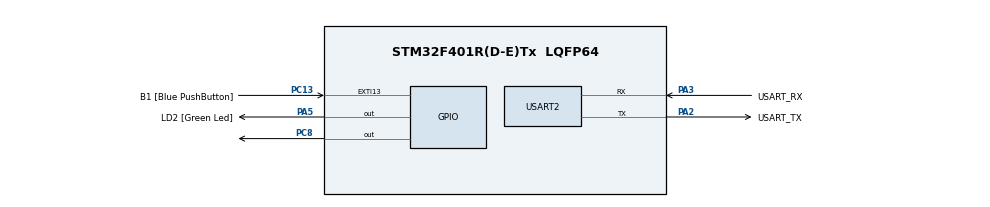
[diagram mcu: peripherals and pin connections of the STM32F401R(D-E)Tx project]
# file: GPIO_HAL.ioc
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Mcu.Family=STM32F4
Mcu.Name=STM32F401R(D-E)Tx
Mcu.Package=LQFP64
NVIC.PriorityGroup=NVIC_PRIORITYGROUP_4
NVIC.USART2_IRQn=true\:3\:0\:true\:false\:true\:true\:true\:true
PA13.GPIO_Label=TMS
PA13.Mode=Serial_Wire
PA13.Signal=SYS_JTMS-SWDIO
PA14.GPIO_Label=TCK
PA14.Mode=Serial_Wire
PA14.Signal=SYS_JTCK-SWCLK
PA2.GPIO_Label=USART_TX
PA2.GPIO_Mode=GPIO_MODE_AF_PP
PA2.GPIO_PuPd=GPIO_NOPULL
PA2.GPIO_Speed=GPIO_SPEED_FREQ_LOW
PA2.Mode=Asynchronous
PA2.Signal=USART2_TX
PA3.GPIO_Label=USART_RX
PA3.GPIO_Mode=GPIO_MODE_AF_PP
PA3.GPIO_PuPd=GPIO_NOPULL
PA3.GPIO_Speed=GPIO_SPEED_FREQ_LOW
PA3.Mode=Asynchronous
PA3.Signal=USART2_RX
PA5.GPIO_Label=LD2 [Green Led]
PA5.GPIO_Mode=GPIO_MODE_OUTPUT_PP
PA5.GPIO_PuPd=GPIO_NOPULL
PA5.GPIO_Speed=GPIO_SPEED_FREQ_LOW
PA5.Signal=GPIO_Output
PB3.GPIO_Label=SWO
PB3.Signal=SYS_JTDO-SWO
PC13-ANTI_TAMP.GPIO_Label=B1 [Blue PushButton]
PC13-ANTI_TAMP.GPIO_ModeDefaultEXTI=GPIO_MODE_IT_FALLING
PC13-ANTI_TAMP.GPIO_PuPd=GPIO_NOPULL
PC13-ANTI_TAMP.Signal=GPXTI13
PC14-OSC32_IN.Mode=LSE-External-Oscillator
PC14-OSC32_IN.Signal=RCC_OSC32_IN
PC15-OSC32_OUT.Mode=LSE-External-Oscillator
PC15-OSC32_OUT.Signal=RCC_OSC32_OUT
PC8.Signal=GPIO_Output
PH0\ -\ OSC_IN.Mode=HSE-External-Clock-Source
PH0\ -\ OSC_IN.Signal=RCC_OSC_IN
PH1\ -\ OSC_OUT.Mode=HSE-External-Clock-Source
PH1\ -\ OSC_OUT.Signal=RCC_OSC_OUT
ProjectManager.HeapSize=0x200
ProjectManager.StackSize=0x400
ProjectManager.TargetToolchain=STM32CubeIDE
RCC.48MHZClocksFreq_Value=48000000
RCC.AHBFreq_Value=84000000
RCC.APB1CLKDivider=RCC_HCLK_DIV2
RCC.APB1Freq_Value=42000000
RCC.APB1TimFreq_Value=84000000
RCC.APB2Freq_Value=84000000
RCC.APB2TimFreq_Value=84000000
RCC.CortexFreq_Value=84000000
RCC.HCLKFreq_Value=84000000
RCC.HSE_VALUE=8000000
RCC.HSI_VALUE=16000000
RCC.PLLN=336
RCC.PLLP=RCC_PLLP_DIV4
RCC.PLLQ=7
RCC.SYSCLKFreq_VALUE=84000000
RCC.SYSCLKSource=RCC_SYSCLKSOURCE_PLLCLK
RCC.VCOOutputFreq_Value=336000000
USART2.VirtualMode=VM_ASYNC
board=NUCLEO-F401RE

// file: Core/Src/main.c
/* USER CODE BEGIN Header */
/**
  ******************************************************************************
  * @file           : main.c
  * @brief          : Main program body
  ******************************************************************************
  * @attention
  *
  * Copyright (c) 2022 STMicroelectronics.
  * All rights reserved.
  *
  * This software is licensed under terms that can be found in the LICENSE file
  * in the root directory of this software component.
  * If no LICENSE file comes with this software, it is provided AS-IS.
  *
  ******************************************************************************
  */
/* USER CODE END Header */
#include "main.h"
#include "usart.h"
#include "gpio.h"

/* USER CODE BEGIN Includes */
#include <string.h>
/* USER CODE END Includes */

/* USER CODE BEGIN PM */
#define NUM 10

/* USER CODE END PM */

/* USER CODE BEGIN PV */
uint8_t numero = 10;

/* USER CODE END PV */

void SystemClock_Config(void);

int main(void)
{

  /* MCU Configuration--------------------------------------------------------*/

  /* Reset of all peripherals, Initializes the Flash interface and the Systick. */
  HAL_Init();

  /* Configure the system clock */
  SystemClock_Config();

  /* Initialize all configured peripherals */
  MX_GPIO_Init();
  MX_USART2_UART_Init();

  /* Infinite loop */
  while (1)
  {

    /* USER CODE BEGIN 3 */
	 HAL_GPIO_TogglePin(GPIOA, GPIO_PIN_5);
	 HAL_Delay(100);
  }
  /* USER CODE END 3 */
}

void SystemClock_Config(void)
{
  LL_FLASH_SetLatency(LL_FLASH_LATENCY_2);
  while(LL_FLASH_GetLatency()!= LL_FLASH_LATENCY_2)
  {
  }
  LL_PWR_SetRegulVoltageScaling(LL_PWR_REGU_VOLTAGE_SCALE2);
  LL_RCC_HSI_SetCalibTrimming(16);
  LL_RCC_HSI_Enable();

   /* Wait till HSI is ready */
  while(LL_RCC_HSI_IsReady() != 1)
  {

  }
  LL_RCC_PLL_ConfigDomain_SYS(LL_RCC_PLLSOURCE_HSI, LL_RCC_PLLM_DIV_16, 336, LL_RCC_PLLP_DIV_4);
  LL_RCC_PLL_Enable();

   /* Wait till PLL is ready */
  while(LL_RCC_PLL_IsReady() != 1)
  {

  }
  LL_RCC_SetAHBPrescaler(LL_RCC_SYSCLK_DIV_1);
  LL_RCC_SetAPB1Prescaler(LL_RCC_APB1_DIV_2);
  LL_RCC_SetAPB2Prescaler(LL_RCC_APB2_DIV_1);
  LL_RCC_SetSysClkSource(LL_RCC_SYS_CLKSOURCE_PLL);

   /* Wait till System clock is ready */
  while(LL_RCC_GetSysClkSource() != LL_RCC_SYS_CLKSOURCE_STATUS_PLL)
  {

  }
  LL_SetSystemCoreClock(84000000);

   /* Update the time base */
  if (HAL_InitTick (TICK_INT_PRIORITY) != HAL_OK)
  {
    Error_Handler();
  }
  LL_RCC_SetTIMPrescaler(LL_RCC_TIM_PRESCALER_TWICE);
}

void Error_Handler(void)
{
  __disable_irq();
  while (1)
  {
  }
}
